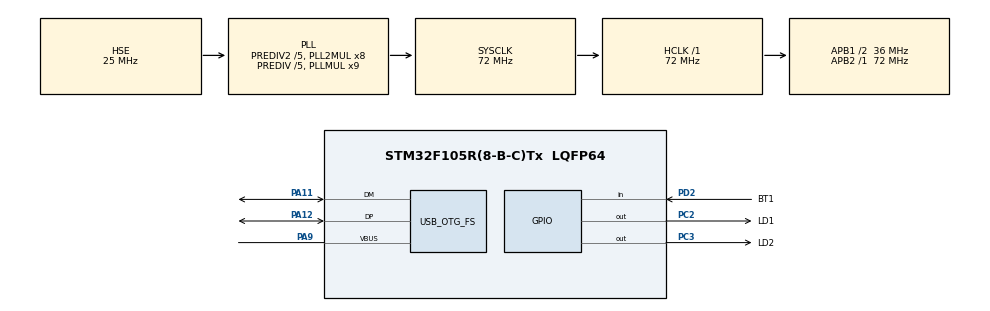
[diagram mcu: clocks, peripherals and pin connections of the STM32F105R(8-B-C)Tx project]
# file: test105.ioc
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FREERTOS.Tasks01=defaultTask,0,128,StartDefaultTask,Default,NULL,Dynamic,NULL,NULL
Mcu.Family=STM32F1
Mcu.Name=STM32F105R(8-B-C)Tx
Mcu.Package=LQFP64
NVIC.OTG_FS_IRQn=true\:5\:0\:false\:false\:true\:true\:false\:true\:true
NVIC.PriorityGroup=NVIC_PRIORITYGROUP_4
NVIC.TIM1_UP_IRQn=true\:15\:0\:false\:false\:true\:false\:false\:true\:true
NVIC.TimeBase=TIM1_UP_IRQn
NVIC.TimeBaseIP=TIM1
PA11.Mode=Device_Only
PA11.Signal=USB_OTG_FS_DM
PA12.Mode=Device_Only
PA12.Signal=USB_OTG_FS_DP
PA13.Mode=Trace_Asynchronous_SW
PA13.Signal=SYS_JTMS-SWDIO
PA14.Mode=Trace_Asynchronous_SW
PA14.Signal=SYS_JTCK-SWCLK
PA9.Mode=Activate_VBUS
PA9.Signal=USB_OTG_FS_VBUS
PB3.Mode=Trace_Asynchronous_SW
PB3.Signal=SYS_TRACESWO
PC2.GPIO_Label=LD1
PC2.Signal=GPIO_Output
PC3.GPIO_Label=LD2
PC3.Signal=GPIO_Output
PD0-OSC_IN.Mode=HSE-External-Oscillator
PD0-OSC_IN.Signal=RCC_OSC_IN
PD1-OSC_OUT.Mode=HSE-External-Oscillator
PD1-OSC_OUT.Signal=RCC_OSC_OUT
PD2.GPIO_Label=BT1
PD2.GPIO_PuPd=GPIO_PULLUP
PD2.Signal=GPIO_Input
ProjectManager.HeapSize=0x800
ProjectManager.StackSize=0x800
ProjectManager.TargetToolchain=Makefile
RCC.AHBFreq_Value=72000000
RCC.APB1CLKDivider=RCC_HCLK_DIV2
RCC.APB1Freq_Value=36000000
RCC.APB1TimFreq_Value=72000000
RCC.APB2Freq_Value=72000000
RCC.APB2TimFreq_Value=72000000
RCC.HCLKFreq_Value=72000000
RCC.HSEDivPLL=RCC_HSE_PREDIV_DIV5
RCC.HSE_VALUE=25000000
RCC.PLLMUL=RCC_PLL_MUL9
RCC.PLLSourceVirtual=RCC_PLLSOURCE_HSE
RCC.Prediv1Source=RCC_PREDIV1_SOURCE_PLL2
RCC.Prediv2=RCC_HSE_PREDIV2_DIV5
RCC.SYSCLKFreq_VALUE=72000000
RCC.SYSCLKSource=RCC_SYSCLKSOURCE_PLLCLK
RCC.USBFreq_Value=48000000
USB_DEVICE.CLASS_NAME_FS=CDC
USB_DEVICE.VirtualMode=Cdc
USB_DEVICE.VirtualModeFS=Cdc_FS
USB_OTG_FS.Sof_enable=DISABLE
USB_OTG_FS.VirtualMode=Device_Only
USB_OTG_FS.low_power_enable=DISABLE
VP_FREERTOS_VS_CMSIS_V1.Mode=CMSIS_V1
VP_SYS_VS_tim1.Mode=TIM1
VP_USB_DEVICE_VS_USB_DEVICE_CDC_FS.Mode=CDC_FS
board=custom

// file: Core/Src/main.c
/* USER CODE BEGIN Header */
/**
  ******************************************************************************
  * @file           : main.c
  * @brief          : Main program body
  ******************************************************************************
  * @attention
  *
  * Copyright (c) 2023 STMicroelectronics.
  * All rights reserved.
  *
  * This software is licensed under terms that can be found in the LICENSE file
  * in the root directory of this software component.
  * If no LICENSE file comes with this software, it is provided AS-IS.
  *
  ******************************************************************************
  */
/* USER CODE END Header */
#include "main.h"
#include "cmsis_os.h"
#include "usb_device.h"

osThreadId defaultTaskHandle;

void SystemClock_Config(void);
static void MX_GPIO_Init(void);
void StartDefaultTask(void const * argument);

int main(void)
{

  /* MCU Configuration--------------------------------------------------------*/

  /* Reset of all peripherals, Initializes the Flash interface and the Systick. */
  HAL_Init();

  /* Configure the system clock */
  SystemClock_Config();

  /* Initialize all configured peripherals */
  MX_GPIO_Init();

  /* Create the thread(s) */
  /* definition and creation of defaultTask */
  osThreadDef(defaultTask, StartDefaultTask, osPriorityNormal, 0, 128);
  defaultTaskHandle = osThreadCreate(osThread(defaultTask), NULL);

  /* Start scheduler */
  osKernelStart();
  /* We should never get here as control is now taken by the scheduler */
  /* Infinite loop */
  while (1)
  {

  }
}

void SystemClock_Config(void)
{
  RCC_OscInitTypeDef RCC_OscInitStruct = {0};
  RCC_ClkInitTypeDef RCC_ClkInitStruct = {0};
  RCC_PeriphCLKInitTypeDef PeriphClkInit = {0};

  /** Initializes the RCC Oscillators according to the specified parameters
  * in the RCC_OscInitTypeDef structure.
  */
  RCC_OscInitStruct.OscillatorType = RCC_OSCILLATORTYPE_HSE;
  RCC_OscInitStruct.HSEState = RCC_HSE_ON;
  RCC_OscInitStruct.HSEPredivValue = RCC_HSE_PREDIV_DIV5;
  RCC_OscInitStruct.HSIState = RCC_HSI_ON;
  RCC_OscInitStruct.Prediv1Source = RCC_PREDIV1_SOURCE_PLL2;
  RCC_OscInitStruct.PLL.PLLState = RCC_PLL_ON;
  RCC_OscInitStruct.PLL.PLLSource = RCC_PLLSOURCE_HSE;
  RCC_OscInitStruct.PLL.PLLMUL = RCC_PLL_MUL9;
  RCC_OscInitStruct.PLL2.PLL2State = RCC_PLL2_ON;
  RCC_OscInitStruct.PLL2.PLL2MUL = RCC_PLL2_MUL8;
  RCC_OscInitStruct.PLL2.HSEPrediv2Value = RCC_HSE_PREDIV2_DIV5;
  if (HAL_RCC_OscConfig(&RCC_OscInitStruct) != HAL_OK)
  {
    Error_Handler();
  }

  /** Initializes the CPU, AHB and APB buses clocks
  */
  RCC_ClkInitStruct.ClockType = RCC_CLOCKTYPE_HCLK|RCC_CLOCKTYPE_SYSCLK
                              |RCC_CLOCKTYPE_PCLK1|RCC_CLOCKTYPE_PCLK2;
  RCC_ClkInitStruct.SYSCLKSource = RCC_SYSCLKSOURCE_PLLCLK;
  RCC_ClkInitStruct.AHBCLKDivider = RCC_SYSCLK_DIV1;
  RCC_ClkInitStruct.APB1CLKDivider = RCC_HCLK_DIV2;
  RCC_ClkInitStruct.APB2CLKDivider = RCC_HCLK_DIV1;

  if (HAL_RCC_ClockConfig(&RCC_ClkInitStruct, FLASH_LATENCY_2) != HAL_OK)
  {
    Error_Handler();
  }
  PeriphClkInit.PeriphClockSelection = RCC_PERIPHCLK_USB;
  PeriphClkInit.UsbClockSelection = RCC_USBCLKSOURCE_PLL_DIV3;
  if (HAL_RCCEx_PeriphCLKConfig(&PeriphClkInit) != HAL_OK)
  {
    Error_Handler();
  }

  /** Configure the Systick interrupt time
  */
  __HAL_RCC_PLLI2S_ENABLE();
}

static void MX_GPIO_Init(void)
{
  GPIO_InitTypeDef GPIO_InitStruct = {0};

  /* GPIO Ports Clock Enable */
  __HAL_RCC_GPIOD_CLK_ENABLE();
  __HAL_RCC_GPIOC_CLK_ENABLE();
  __HAL_RCC_GPIOA_CLK_ENABLE();
  __HAL_RCC_GPIOB_CLK_ENABLE();

  /*Configure GPIO pin Output Level */
  HAL_GPIO_WritePin(GPIOC, LD1_Pin|LD2_Pin, GPIO_PIN_RESET);

  /*Configure GPIO pins : LD1_Pin LD2_Pin */
  GPIO_InitStruct.Pin = LD1_Pin|LD2_Pin;
  GPIO_InitStruct.Mode = GPIO_MODE_OUTPUT_PP;
  GPIO_InitStruct.Pull = GPIO_NOPULL;
  GPIO_InitStruct.Speed = GPIO_SPEED_FREQ_LOW;
  HAL_GPIO_Init(GPIOC, &GPIO_InitStruct);

  /*Configure GPIO pin : BT1_Pin */
  GPIO_InitStruct.Pin = BT1_Pin;
  GPIO_InitStruct.Mode = GPIO_MODE_INPUT;
  GPIO_InitStruct.Pull = GPIO_PULLUP;
  HAL_GPIO_Init(BT1_GPIO_Port, &GPIO_InitStruct);

}

void StartDefaultTask(void const * argument)
{
  /* init code for USB_DEVICE */
  MX_USB_DEVICE_Init();
  /* USER CODE BEGIN 5 */
  /* Infinite loop */
  for(;;)
  {
    extern void userCoreInit(void);
    userCoreInit();
    osThreadSuspend(NULL);
  }
  /* USER CODE END 5 */
}

void HAL_TIM_PeriodElapsedCallback(TIM_HandleTypeDef *htim)
{
  if (htim->Instance == TIM1) {
    HAL_IncTick();
  }
}

void Error_Handler(void)
{
  __disable_irq();
  while (1)
  {
  }
}
